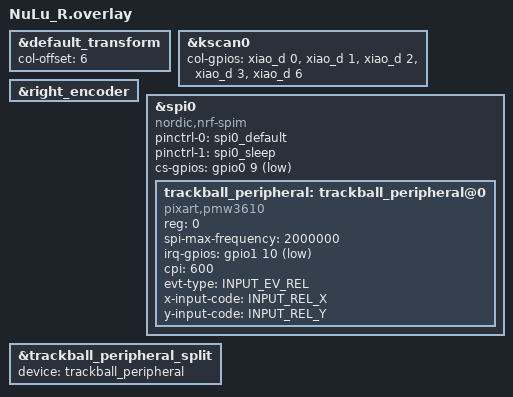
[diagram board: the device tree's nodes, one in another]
#include "NuLu.dtsi"
#include <zephyr/dt-bindings/input/input-event-codes.h>

&default_transform {
    col-offset = <6>;
};

&kscan0 {
        col-gpios
            = <&xiao_d 0 GPIO_ACTIVE_HIGH>
            , <&xiao_d 1 GPIO_ACTIVE_HIGH> 
            , <&xiao_d 2 GPIO_ACTIVE_HIGH> 
            , <&xiao_d 3 GPIO_ACTIVE_HIGH> 
            , <&xiao_d 6 GPIO_ACTIVE_HIGH>
            ;
};

&right_encoder {
    status = "okay";
};

&spi0 {
    status = "okay";
    compatible = "nordic,nrf-spim";
    pinctrl-0 = <&spi0_default>;
    pinctrl-1 = <&spi0_sleep>;
    pinctrl-names = "default", "sleep";
    cs-gpios = <&gpio0 9 GPIO_ACTIVE_LOW>;

    trackball_peripheral: trackball_peripheral@0 {
        status = "okay";
        compatible = "pixart,pmw3610";
        reg = <0>;
        spi-max-frequency = <2000000>;
        irq-gpios = <&gpio1 10 (GPIO_ACTIVE_LOW | GPIO_PULL_UP)>;
        cpi = <600>;
        evt-type = <INPUT_EV_REL>;
        x-input-code = <INPUT_REL_X>;
        y-input-code = <INPUT_REL_Y>;
    };
};

&trackball_peripheral_split {
    status = "okay";
    device = <&trackball_peripheral>;
};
